# RL6678_IP_SVD register map
Vendor: Realtek
Registers are 32-bit, read-write, reset 0x0 unless marked. A register's access mark holds for its fields unless they carry their own. Offsets are from the block's base; [hi:lo] are bit positions; lines under a group give offsets from that group; {n}, {i} and the like mark numbered series.

## PAGE6 (part 2 of 3)
Base 0x40000000
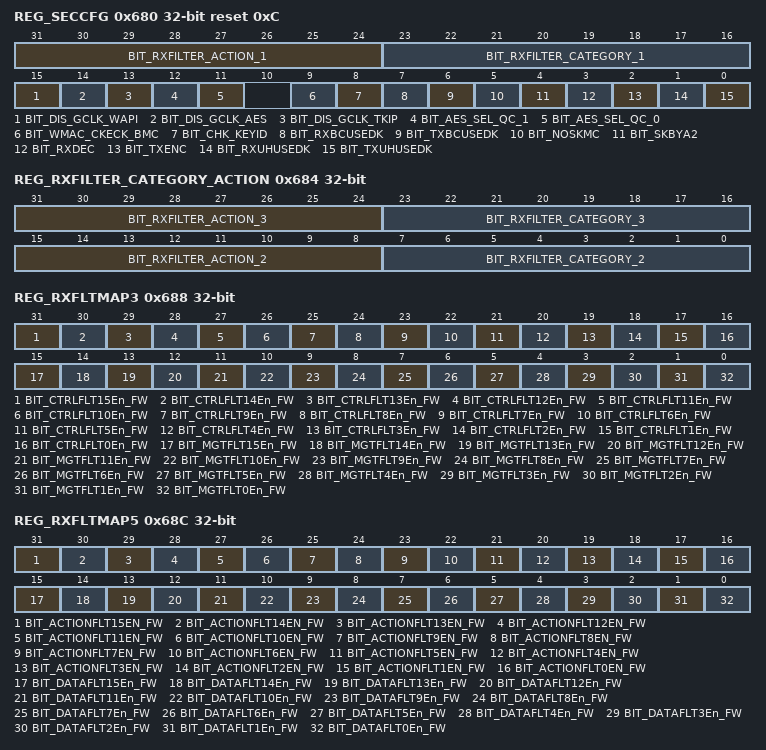
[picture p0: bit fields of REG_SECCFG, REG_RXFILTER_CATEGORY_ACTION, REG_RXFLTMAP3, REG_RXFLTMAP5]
0x680 REG_SECCFG reset 0xC — Security Configuration Register
  [31:24] BIT_RXFILTER_ACTION_1 — Configured by FW, Refer to 0x68E[10] to decide accepting this frame or not
  [23:16] BIT_RXFILTER_CATEGORY_1 — Configured by FW, Refer to 0x68E[10] to decide accepting this frame or not
  [15] BIT_DIS_GCLK_WAPI — Disable gated clock control for WAPI engine
  [14] BIT_DIS_GCLK_AES — Disable gated clock control for AES engine.
  [13] BIT_DIS_GCLK_TKIP — Disable gated clock control for WEP/TKIP engine.
  [12] BIT_AES_SEL_QC_1 — 1: use QC[7] to compute mic 0: not use QC[7] to compute mic
  [11] BIT_AES_SEL_QC_0 — 1:use QC[7] to compute ctr 0: not use QC[7] to compute ctr
  [9] BIT_WMAC_CKECK_BMC — If this bit is set to 1, key search engine need to check if broadcast/multicast bit matched.
  [8] BIT_CHK_KEYID — If this bit is set to 1, key search engine need to check if key ID matched. If this bit is set to 0, then key ID table must be filled with 2"b00.
  [7] BIT_RXBCUSEDK — Force RX Broadcast packets Use Default Key If this bit is set to 1, use default key for RX key search when received packet is broadcast and multicast.
  [6] BIT_TXBCUSEDK — Force Tx Broadcast packets Use Default Key If this bit is set to 1, use default key for TX key search when transmitted packet is broadcast and multicast.
  [5] BIT_NOSKMC — No Key Search for Multicast Setting 1 to disable key search for multicast frames. Used in MBSSID AP mode. Software should manage security encryption and decryption.
  [4] BIT_SKBYA2 — Search Key by A2 Setting 1 to search security CAM by address 2 for TX and search CAM by address 1 for RX. Setting 0 to search security CAM by address 1 for TX and search CAM by address 2 for RX. Used in MBSSID client mode.
  [3] BIT_RXDEC — Enable Rx Decryption Setting 1 to enable Rx hardware decryption.
  [2] BIT_TXENC — Enable Tx Encryption Setting to 1 to enable Tx hardware encryption.
  [1] BIT_RXUHUSEDK — Force RX Unicast Use Default Key If this bit is set to 1, use default key for RX key search when pairwise key is not found.
  [0] BIT_TXUHUSEDK — Force Tx Unicast Use Default Key If this bit is set to 1, use default key for TX key search when pairwise key is not found.
0x684 REG_RXFILTER_CATEGORY_ACTION
  [31:24] BIT_RXFILTER_ACTION_3 — Configured by FW, Refer to 0x68E[15] to decide accepting this frame or not
  [23:16] BIT_RXFILTER_CATEGORY_3 — Configured by FW, Refer to 0x68E[15] to decide accepting this frame or not
  [15:8] BIT_RXFILTER_ACTION_2 — Configured by FW, Refer to 0x68E[11] to decide accepting this frame or not
  [7:0] BIT_RXFILTER_CATEGORY_2 — Configured by FW, Refer to 0x68E[11] to decide accepting this frame or not
0x688 REG_RXFLTMAP3 — RX Filter Map Group 0
  [31] BIT_CTRLFLT15En_FW — When set, frames with type=01 and subtype=1111 are received into FWFF.
  [30] BIT_CTRLFLT14En_FW — When set, frames with type=01 and subtype=1110 are received into FWFF.
  [29] BIT_CTRLFLT13En_FW — When set, frames with type=01 and subtype=1101 are received into FWFF.
  [28] BIT_CTRLFLT12En_FW — When set, frames with type=01 and subtype=1100 are received into FWFF.
  [27] BIT_CTRLFLT11En_FW — When set, frames with type=01 and subtype=1011 are received into FWFF.
  [26] BIT_CTRLFLT10En_FW — When set, frames with type=01 and subtype=1010 are received into FWFF.
  [25] BIT_CTRLFLT9En_FW — When set, frames with type=01 and subtype=1001 are received into FWFF.
  [24] BIT_CTRLFLT8En_FW — When set, frames with type=01 and subtype=1000 are received into FWFF.
  [23] BIT_CTRLFLT7En_FW — When set, frames with type=01 and subtype=0111 are received into FWFF.
  [22] BIT_CTRLFLT6En_FW — When set, frames with type=01 and subtype=0110 are received into FWFF.
  [21] BIT_CTRLFLT5En_FW — When set, frames with type=01 and subtype=0101 are received into FWFF.
  [20] BIT_CTRLFLT4En_FW — When set, frames with type=01 and subtype=0100 are received into FWFF.
  [19] BIT_CTRLFLT3En_FW — When set, frames with type=01 and subtype=0011 are received into FWFF.
  [18] BIT_CTRLFLT2En_FW — When set, frames with type=01 and subtype=0010 are received into FWFF.
  [17] BIT_CTRLFLT1En_FW — When set, frames with type=01 and subtype=0001 are received into FWFF.
  [16] BIT_CTRLFLT0En_FW — When set, frames with type=01 and subtype=0000 are received into FWFF.
  [15] BIT_MGTFLT15En_FW — When set, frames with type=00 and subtype=1111 are received into FWFF.
  [14] BIT_MGTFLT14En_FW — When set, all the frames with type=00 and subtype=1110 are received into FWFF. When set to 0, refer to 0x68E[15:12] for deciding which action noack frames will be accepted
  [13] BIT_MGTFLT13En_FW — When set, all the frames with type=00 and subtype=1101 are received into FWFF. When set to 0, refer to 0x68E[11:0] for deciding which action frames will be accepted
  [12] BIT_MGTFLT12En_FW — When set, frames with type=00 and subtype=1100 are received into FWFF.
  [11] BIT_MGTFLT11En_FW — When set, frames with type=00 and subtype=1011 are received into FWFF.
  [10] BIT_MGTFLT10En_FW — When set, frames with type=00 and subtype=1010 are received into FWFF.
  [9] BIT_MGTFLT9En_FW — When set, frames with type=00 and subtype=1001 are received into FWFF.
  [8] BIT_MGTFLT8En_FW — When set, frames with type=00 and subtype=1000 are received into FWFF.
  [7] BIT_MGTFLT7En_FW — When set, frames with type=00 and subtype=0111 are received into FWFF.
  [6] BIT_MGTFLT6En_FW — When set, frames with type=00 and subtype=0110 are received into FWFF.
  [5] BIT_MGTFLT5En_FW — When set, frames with type=00 and subtype=0101 are received into FWFF.
  [4] BIT_MGTFLT4En_FW — When set, frames with type=00 and subtype=0100 are received into FWFF.
  [3] BIT_MGTFLT3En_FW — When set, frames with type=00 and subtype=0011 are received into FWFF.
  [2] BIT_MGTFLT2En_FW — When set, frames with type=00 and subtype=0010 are received into FWFF.
  [1] BIT_MGTFLT1En_FW — When set, frames with type=00 and subtype=0001 are received into FWFF.
  [0] BIT_MGTFLT0En_FW — When set, frames with type=00 and subtype=0000 are received into FWFF.
0x68C REG_RXFLTMAP5 — RX Filter Map Group 1
  [31] BIT_ACTIONFLT15EN_FW — When set, Action noack frame with category = r_RXFILTER_CATEGORY_3(0x686[7:0]) and action = r_RXFILTER_ACTION_3(0x687[7:0]) will be received into FWFF
  [30] BIT_ACTIONFLT14EN_FW — When set, VHT compressed beamforming frame will be received into FWFF.
  [29] BIT_ACTIONFLT13EN_FW — When set, HT compressed beamforming frame will be received into FWFF.
  [28] BIT_ACTIONFLT12EN_FW — When set, CSI frame will be received into FWFF.
  [27] BIT_ACTIONFLT11EN_FW — When set, Action frame with category = r_RXFILTER_CATEGORY_2(0x684[7:0]) and action = r_RXFILTER_ACTION_2(0x685[7:0]) will be received into FWFF
  [26] BIT_ACTIONFLT10EN_FW — When set, Action frame with category = r_RXFILTER_CATEGORY_1(0x682[7:0]) and action = r_RXFILTER_ACTION_1(0x683[7:0]) will be received into FWFF
  [25] BIT_ACTIONFLT9EN_FW — When set, Operating mode notification frame will be received into FWFF.
  [24] BIT_ACTIONFLT8EN_FW — When set, Group ID Management frame will be received into FWFF.
  [23] BIT_ACTIONFLT7EN_FW — When set, Notify channel width frame will be received into FWFF.
  [22] BIT_ACTIONFLT6EN_FW — When set, DELBA frame will be received into FWFF.
  [21] BIT_ACTIONFLT5EN_FW — When set, ADDBA Response frame will be received into FWFF.
  [20] BIT_ACTIONFLT4EN_FW — When set, ADDBA Request frame will be received into FWFF.
  [19] BIT_ACTIONFLT3EN_FW — When set, DELTS frame will be received into FWFF.
  [18] BIT_ACTIONFLT2EN_FW — When set, ADDTS Response frame will be received into FWFF.
  [17] BIT_ACTIONFLT1EN_FW — When set, ADDTS Request frame will be received into FWFF.
  [16] BIT_ACTIONFLT0EN_FW — When set, Channel Switch Announcement frame will be received into FWFF.
  [15] BIT_DATAFLT15En_FW — When set, frames with type=10 and subtype=1111 are received into FWFF.
  [14] BIT_DATAFLT14En_FW — When set, frames with type=10 and subtype=1110 are received into FWFF.
  [13] BIT_DATAFLT13En_FW — When set, frames with type=10 and subtype=1101 are received into FWFF.
  [12] BIT_DATAFLT12En_FW — When set, frames with type=10 and subtype=1100 are received into FWFF.
  [11] BIT_DATAFLT11En_FW — When set, frames with type=10 and subtype=1011 are received into FWFF.
  [10] BIT_DATAFLT10En_FW — When set, frames with type=10 and subtype=1010 are received into FWFF.
  [9] BIT_DATAFLT9En_FW — When set, frames with type=10 and subtype=1001 are received into FWFF.
  [8] BIT_DATAFLT8En_FW — When set, frames with type=10 and subtype=1000 are received into FWFF.
  [7] BIT_DATAFLT7En_FW — When set, frames with type=10 and subtype=0111 are received into FWFF.
  [6] BIT_DATAFLT6En_FW — When set, frames with type=10 and subtype=0110 are received into FWFF.
  [5] BIT_DATAFLT5En_FW — When set, frames with type=10 and subtype=0101 are received into FWFF.
  [4] BIT_DATAFLT4En_FW — When set, frames with type=10 and subtype=0100 are received into FWFF.
  [3] BIT_DATAFLT3En_FW — When set, frames with type=10 and subtype=0011 are received into FWFF.
  [2] BIT_DATAFLT2En_FW — When set, frames with type=10 and subtype=0010 are received into FWFF.
  [1] BIT_DATAFLT1En_FW — When set, frames with type=10 and subtype=0001 are received into FWFF.
  [0] BIT_DATAFLT0En_FW — When set, frames with type=10 and subtype=0000 are received into FWFF.
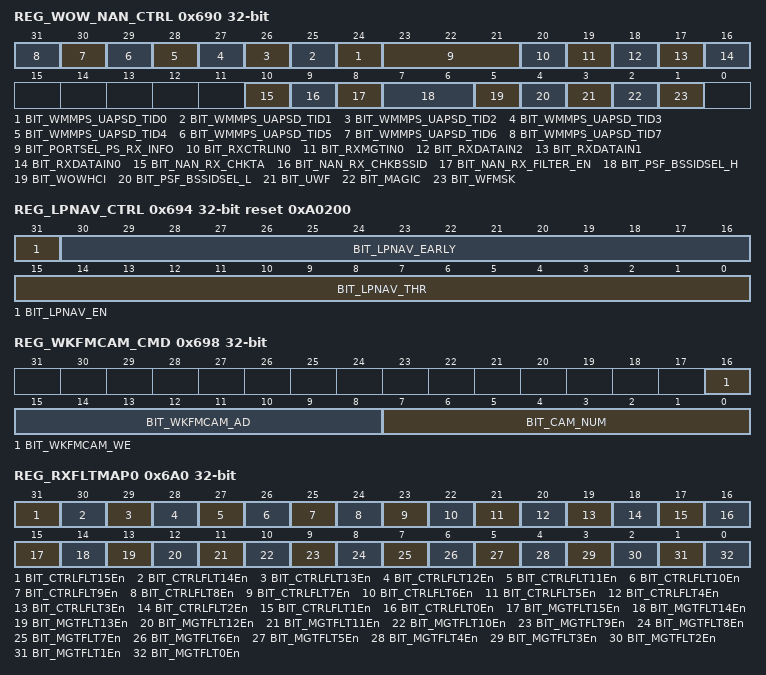
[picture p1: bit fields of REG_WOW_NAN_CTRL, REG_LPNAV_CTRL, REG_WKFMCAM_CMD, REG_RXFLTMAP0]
0x690 REG_WOW_NAN_CTRL access per field — Wake On WLAN and NAN Control Register
  [n+24] BIT_WMMPS_UAPSD_TID{n} rw (n=0..7) — Disable interrupt 8051 when rx WMMPS UAPSD Qos data with TID{n}
  [23:21] BIT_PORTSEL_PS_RX_INFO rw — The selector for the source of PS RX information (0x692[4:0]). 0 for port 0, 1 for clint0, 2 for clint1, 3 for clint2, 4 for clint3.
  [20] BIT_RXCTRLIN0 ro — It is set to 1 if NIC received control frame with correct DA.
  [19] BIT_RXMGTIN0 ro — It is set to 1 if NIC received management frame with correct BSSID and DA (including unicast and BMC).
  [18] BIT_RXDATAIN2 ro — It is set to 1 if NIC received data frame with correct BSSID and DA (including unicast and BMC).
  [17] BIT_RXDATAIN1 ro — It is set to 1 if NIC received data frame with correct BSSID and DA (including unicast and BMC).
  [16] BIT_RXDATAIN0 ro — It is set to 1 if NIC received data frame with correct BSSID and DA (including unicast and BMC).
  [10] BIT_NAN_RX_CHKTA rw — Enable bit for check TSF filter When set to 1, the TSF address filter will enable. When set to 0, the TSF address filter will disable.
  [9] BIT_NAN_RX_CHKBSSID rw — Check BSSID_BCN for TSF When set to 1, MAC will check the BSSID (A3) of RX beacon or Probe to determine if this packet will sync TSF or not
  [8] BIT_NAN_RX_FILTER_EN rw — When set to 1, the TSF address filter will enable. When set to 0, the TSF address filter will disable.
  [7:6] BIT_PSF_BSSIDSEL_H rw — Bit 1,2 of Select to check the MACID of which port for the WMAC PSF NSARP function. 0: to check the MACID of port0; 1: to check the MACID of port1. 2: to check the MACID of port2. 3: to check the MACID of port3. 4: to check the MACID of port4.
  [5] BIT_WOWHCI rw — This bit is set to allow wake host as wake on wlan event occurring
  [4] BIT_PSF_BSSIDSEL_L rw — Bit 0 of Select to check the MACID of which port for the WMAC PSF NSARP function. 0: to check the MACID of port0; 1: to check the MACID of port1. 2: to check the MACID of port2. 3: to check the MACID of port3. 4: to check the MACID of port4.
  [3] BIT_UWF rw — Unicast Packet. 1: Enable to check packet"s DA match MAC address or not. 0: Disable. (default value)
  [2] BIT_MAGIC rw — Magic Packet. This bit is valid when the PMEn bit of the PMR register is set. The RTL8192 will assert the PMEB signal to wakeup the operating system when a Magic Packet is received. Once the RTL8192 has been enabled for Magic Packet wakeup, it scans incoming packets addressed to the node for a data sequence. The correct sequence indicates to the controller that this is a Magic Packet frame. A Magic Packet frame must also meet the basic requirements: Frame Control + Duration/ID + Destination address + Address 2 + Address 3 + Sequence Control + data + CRC. The destination address may be the node ID of the receiving station or a multicast address, including the broadcast address. The specific sequence consists of 16 duplications of 6 byte ID registers, with no breaks or interrupts. This sequence can be located anywhere within the packet, but must be preceded by a synchronization stream, 6 bytes of FFh. The device will also accept a multicast address, as long as the 16 duplications of the IEEE address match the address of the ID registers. If the Node ID is 11h 22h 33h 44h 55h 66h, then the magic frame"s format is as follows: Frame Control + Duration/ID + Destination address + Address 2 + Address 3 + Sequence Control + MISC + FF FF FF FF FF FF + MISC + 11 22 33 44 55 66 + 11 22 33 44 55 66 + 11 22 33 44 55 66 + 11 22 33 44 55 66 + 11 22 33 44 55 66 + 11 22 33 44 55 66 + 11 22 33 44 55 66 + 11 22 33 44 55 66 + 11 22 33 44 55 66 + 11 22 33 44 55 66 + 11 22 33 44 55 66 + 11 22 33 44 55 66 + 11 22 33 44 55 66 + 11 22 33 44 55 66 + 11 22 33 44 55 66 + 11 22 33 44 55 66 + MISC + CRC.
  [1] BIT_WFMSK rw — WoW function on or off.
0x694 REG_LPNAV_CTRL reset 0xA0200 — Low Power NAV Control Register
  [31] BIT_LPNAV_EN — Low Power NAV Mode Enable. When this bit is set, enable MAC low power NAV mode
  [30:16] BIT_LPNAV_EARLY — When in LPNAV mode, MAC will recall BB and RF into RX idle mode. The unit is us.
  [15:0] BIT_LPNAV_THR — When protected NAV in the received frame is greater than this threshold value, then MAC enters into LPNAV mode. The time unit is 16us.
0x698 REG_WKFMCAM_CMD — Wakeup Frame CAM Number Register
  [16] BIT_WKFMCAM_WE — CAM Write Enable
  [15:8] BIT_WKFMCAM_AD — Entry address
  [7:0] BIT_CAM_NUM — CAM Entry Number
0x69C REG_WKFMCAM_WD — Wakeup Frame CAM CONTENT Register
  [31:0] BIT_WKFMCAM_WD — CAM Write Data
0x6A0 REG_RXFLTMAP0 — RX Filter Map Group 0
  [31] BIT_CTRLFLT15En — When set, frames with type=01 and subtype=1111 are received into RXFF
  [30] BIT_CTRLFLT14En — When set, frames with type=01 and subtype=1110 are received into RXFF
  [29] BIT_CTRLFLT13En — When set, frames with type=01 and subtype=1101 are received into RXFF.
  [28] BIT_CTRLFLT12En — When set, frames with type=01 and subtype=1100 are received into RXFF.
  [27] BIT_CTRLFLT11En — When set, frames with type=01 and subtype=1011 are received into RXFF
  [26] BIT_CTRLFLT10En — When set, frames with type=01 and subtype=1010 are received into RXFF.
  [25] BIT_CTRLFLT9En — When set, frames with type=01 and subtype=1001 are received into RXFF
  [24] BIT_CTRLFLT8En — When set, frames with type=01 and subtype=1000 are received into RXFF
  [23] BIT_CTRLFLT7En — When set, frames with type=01 and subtype=0111 are received into RXFF
  [22] BIT_CTRLFLT6En — When set, frames with type=01 and subtype=0110 are received into RXFF.
  [21] BIT_CTRLFLT5En — When set, frames with type=01 and subtype=0101 are received into RXFF.
  [20] BIT_CTRLFLT4En — When set, frames with type=01 and subtype=0100 are received into RXFF.
  [19] BIT_CTRLFLT3En — When set, frames with type=01 and subtype=0011 are received into RXFF.
  [18] BIT_CTRLFLT2En — When set, frames with type=01 and subtype=0010 are received into RXFF.
  [17] BIT_CTRLFLT1En — When set, frames with type=01 and subtype=0001 are received into RXFF.
  [16] BIT_CTRLFLT0En — When set, frames with type=01 and subtype=0000 are received into RXFF.
  [15] BIT_MGTFLT15En — When set, frames with type=00 and subtype=1111 are received into RXFF.
  [14] BIT_MGTFLT14En — When set, frames with type=00 and subtype=1110 are received into RXFF.
  [13] BIT_MGTFLT13En — When set, frames with type=00 and subtype=1101 are received into RXFF.
  [12] BIT_MGTFLT12En — When set, frames with type=00 and subtype=1100 are received into RXFF.
  [11] BIT_MGTFLT11En — When set, frames with type=00 and subtype=1011 are received into RXFF.
  [10] BIT_MGTFLT10En — When set, frames with type=00 and subtype=1010 are received into RXFF
  [9] BIT_MGTFLT9En — When set, frames with type=00 and subtype=1001 are received into RXFF.
  [8] BIT_MGTFLT8En — When set, frames with type=00 and subtype=1000 are received into RXFF
  [7] BIT_MGTFLT7En — When set, frames with type=00 and subtype=0111 are received into RXFF.
  [6] BIT_MGTFLT6En — When set, frames with type=00 and subtype=0110 are received into RXFF.
  [5] BIT_MGTFLT5En — When set, frames with type=00 and subtype=0101 are received into RXFF
  [4] BIT_MGTFLT4En — When set, frames with type=00 and subtype=0100 are received into RXFF.
  [3] BIT_MGTFLT3En — When set, frames with type=00 and subtype=0011 are received into RXFF
  [2] BIT_MGTFLT2En — When set, frames with type=00 and subtype=0010 are received into RXFF
  [1] BIT_MGTFLT1En — When set, frames with type=00 and subtype=0001 are received into RXFF
  [0] BIT_MGTFLT0En — When set, frames with type=00 and subtype=0000 are received into RXFF
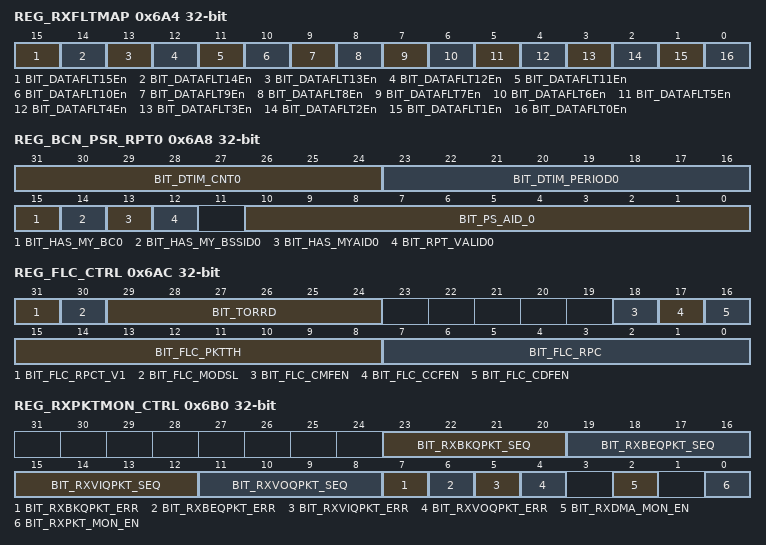
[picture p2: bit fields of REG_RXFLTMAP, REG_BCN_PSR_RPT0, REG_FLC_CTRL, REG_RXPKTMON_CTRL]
0x6A4 REG_RXFLTMAP — RX Filter Map Group 1
  [15] BIT_DATAFLT15En — When set, frames with type=10 and subtype=1111 are received into RXFF
  [14] BIT_DATAFLT14En — When set, frames with type=10 and subtype=1110 are received into RXFF
  [13] BIT_DATAFLT13En — When set, frames with type=10 and subtype=1101 are received into RXFF.
  [12] BIT_DATAFLT12En — When set, frames with type=10 and subtype=1100 are received into RXFF.
  [11] BIT_DATAFLT11En — When set, frames with type=10 and subtype=1011 are received into RXFF.
  [10] BIT_DATAFLT10En — When set, frames with type=10 and subtype=1010 are received into RXFF.
  [9] BIT_DATAFLT9En — When set, frames with type=10 and subtype=1001 are received into RXFF
  [8] BIT_DATAFLT8En — When set, frames with type=10 and subtype=1000 are received into RXFF
  [7] BIT_DATAFLT7En — When set, frames with type=10 and subtype=0111 are received into RXFF.
  [6] BIT_DATAFLT6En — When set, frames with type=10 and subtype=0110 are received into RXFF
  [5] BIT_DATAFLT5En — When set, frames with type=10 and subtype=0101 are received into RXFF
  [4] BIT_DATAFLT4En — When set, frames with type=10 and subtype=0100 are received into RXFF.
  [3] BIT_DATAFLT3En — When set, frames with type=10 and subtype=0011 are received into RXFF
  [2] BIT_DATAFLT2En — When set, frames with type=10 and subtype=0010 are received into RXFF.
  [1] BIT_DATAFLT1En — When set, frames with type=10 and subtype=0001 are received into RXFF.
  [0] BIT_DATAFLT0En — When set, frames with type=10 and subtype=0000 are received into RXFF.
0x6A8 REG_BCN_PSR_RPT0 access per field — Beacon Parser Report Register
  [31:24] BIT_DTIM_CNT0 ro — The DTIM count field of the TIM element of Rx beacon
  [23:16] BIT_DTIM_PERIOD0 ro — The DTIM period field of the TIM element of Rx beacon
  [15] BIT_HAS_MY_BC0 ro — Indicate BC/MC packets are buffered in transmitted BSSID or AP
  [14] BIT_HAS_MY_BSSID0 ro — Indicate BC/MC packets are buffered in nontransmitted BSSID, SW need check crespponding dtim count field in multiple bssid index field
  [13] BIT_HAS_MYAID0 ro — Indicate has my unicast packet
  [12] BIT_RPT_VALID0 ro — when set to 1, indicate the tim report is valid
  [10:0] BIT_PS_AID_0 rw — AID0 for MACID
0x6AC REG_FLC_CTRL access per field — FW LPS Condition PKT Counter
  [31] BIT_FLC_RPCT_V1 rw — When write "1" to this bit, FLC_TRPC will be enabled.
  [30] BIT_FLC_MODSL rw — 1:Timer Mode 0:Counter Mode
  [29:24] BIT_TORRD rw — It specifies the time-out duration. (unit: 32 ms)
  [18] BIT_FLC_CMFEN rw — Count Management Frame (1: Enable, 0:Disable)
  [17] BIT_FLC_CCFEN rw — Count Control Frame (1: Enable, 0:Disable)
  [16] BIT_FLC_CDFEN rw — Count Data Frame (1: Enable, 0:Disable)
  [15:8] BIT_FLC_PKTTH rw — Rx PKT number threshold
  [7:0] BIT_FLC_RPC ro — Number of Rx PKT in the interval which is specified by FLC_TRPC. The Rx PKT type is specified by 0x6AE[2:0]
0x6B0 REG_RXPKTMON_CTRL access per field
  [23:20] BIT_RXBKQPKT_SEQ ro — The expected Rx BKQ packet index
  [19:16] BIT_RXBEQPKT_SEQ ro — The expected Rx BEQ packet index
  [15:12] BIT_RXVIQPKT_SEQ ro — The expected Rx VIQ packet index
  [11:8] BIT_RXVOQPKT_SEQ ro — The expected Rx VOQ packet index
  [7] BIT_RXBKQPKT_ERR ro — Indicate monitor find the Rx BKQ packet without incremental index
  [6] BIT_RXBEQPKT_ERR ro — Indicate monitor find the Rx BEQ packet without incremental index
  [5] BIT_RXVIQPKT_ERR ro — Indicate monitor find the Rx VIQ packet without incremental index
  [4] BIT_RXVOQPKT_ERR ro — Indicate monitor find the Rx VOQ packet without incremental index
  [2] BIT_RXDMA_MON_EN rw — Enable packet loss monitor function for Rx DMA. If this bit is set to 1, then MACRX append the incremental index to fragment field of sequence number field of rxmpdu restored to rxpkbuffer successfully
  [0] BIT_RXPKT_MON_EN rw — Enable packet loss monitor function for Rx packets. If this bit is set to 1, then MACRX uses fragment field of sequence number field of rxmpdu as the mpdu index and check if the index is incremental.
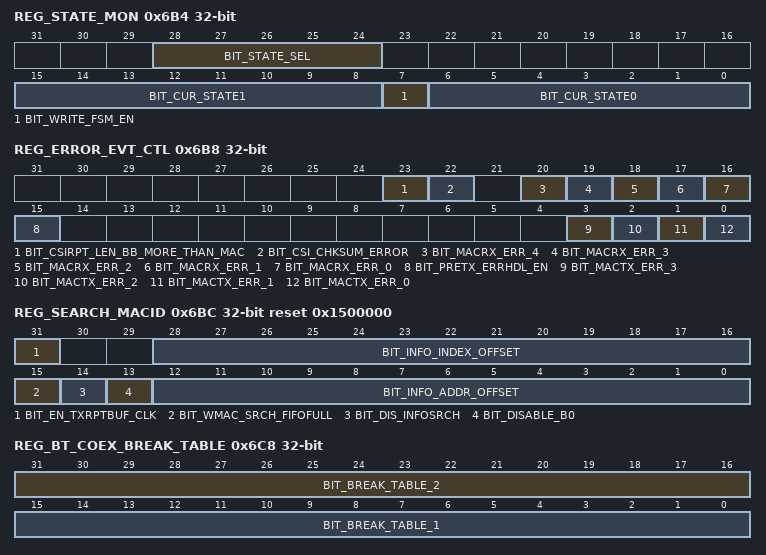
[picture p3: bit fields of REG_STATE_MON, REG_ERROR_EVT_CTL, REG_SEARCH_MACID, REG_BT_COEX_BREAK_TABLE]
0x6B4 REG_STATE_MON access per field
  [28:24] BIT_STATE_SEL rw — WMAC read and write FSM selection: 000,001:read mactx status 010,011:read mactx status 100:read response status 00xxx: write [6:0]to mactx fsm when [7] valid 01xxx:write [6:0]to macrx fsm when [7] valid 100xx: write [6:0]to response fsm when [7] valid
  [15:8] BIT_CUR_STATE1 ro — when BIT_WRITE_FSM_EN is valid,is rsvd. When BIT_WRITE_FSM_EN is not valid, means read status
  [7] BIT_WRITE_FSM_EN ro — when set 1, generate write pulse, otherwise means read status
  [6:0] BIT_CUR_STATE0 rw — when BIT_WRITE_FSM_EN is valid,Indicate the FSM current state to write. When BIT_WRITE_FSM_EN is not valid, means read status
0x6B8 REG_ERROR_EVT_CTL access per field
  [23] BIT_CSIRPT_LEN_BB_MORE_THAN_MAC ro — Indicate MAC Rx csi rxd number overflow
  [22] BIT_CSI_CHKSUM_ERROR ro — Indicate MAC Rx csi rpt checksum error
  [20] BIT_MACRX_ERR_4 ro — Indicate last MPDU length of AMPDU or PPDU length is error.
  [19] BIT_MACRX_ERR_3 ro — Indicate rxfifo or mac phy interface fifo overflow
  [18] BIT_MACRX_ERR_2 ro — Indicate MAC Rx occurs internal halt event
  [17] BIT_MACRX_ERR_1 ro — Indicate Rx packet length >= 12K bytes
  [16] BIT_MACRX_ERR_0 ro — Indicate MAC Rx occurs halt event
  [15] BIT_PRETX_ERRHDL_EN rw — Pre tx error block enable signal
  [3] BIT_MACTX_ERR_3 ro — Indicate PHY fetch plcp before it is ready
  [2] BIT_MACTX_ERR_2 ro — phy_txen is set ,but wait phy_phytxon time out
  [1] BIT_MACTX_ERR_1 ro — Indicate TXD FIFO underflow,ppdu fetch zld
  [0] BIT_MACTX_ERR_0 ro — Indicate TXD FIFO underflow,mpdu fetch zld
0x6BC REG_SEARCH_MACID reset 0x1500000
  [31] BIT_EN_TXRPTBUF_CLK — when set to 1,keep txrptbuf sram always have clock
  [28:16] BIT_INFO_INDEX_OFFSET — Pre-macid information index address offset.
  [15] BIT_WMAC_SRCH_FIFOFULL — when set to 1, when fifofull, stop macid search;
  [14] BIT_DIS_INFOSRCH — when set to 1,disable to search information
  [13] BIT_DISABLE_B0 — when set to 1,disable to check a2[0]
  [12:0] BIT_INFO_ADDR_OFFSET — per-macid information address offset (Unit:8bytes).
0x6C0 REG_BT_COEX_TABLE_V1 — BT Coexistence Control register
  [31:0] BIT_COEX_TABLE_1 — coexistence table, used at dual antenna & out of band
0x6C4 REG_BT_COEX_TABLE2_V1 — BTCoexistence Control register
  [31:0] BIT_COEX_TABLE_2 — coexistence table, used at dual antenna & in band or single antenna
0x6C8 REG_BT_COEX_BREAK_TABLE — BT Coexistence Control register
  [31:16] BIT_BREAK_TABLE_2 — Table used to break BT activity, when new WLAN request is coming and BT is on transmitting or receiving
  [15:0] BIT_BREAK_TABLE_1 — Table used to break WLAN activity, when new BT request is coming and WLAN is on transmitting or receiving
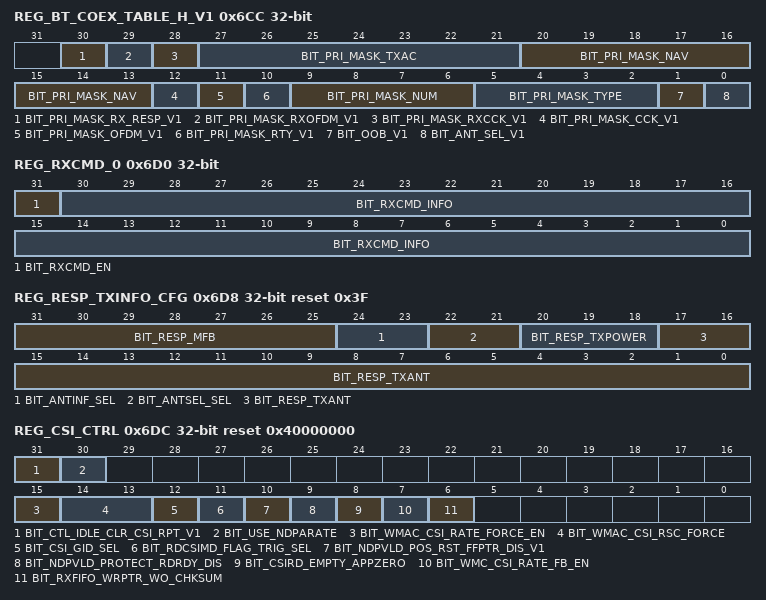
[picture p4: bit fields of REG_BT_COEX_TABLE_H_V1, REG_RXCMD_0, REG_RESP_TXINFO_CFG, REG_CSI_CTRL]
0x6CC REG_BT_COEX_TABLE_H_V1 — BT Coexistence Control register
  [30] BIT_PRI_MASK_RX_RESP_V1 — Priority Mask for RX Response Packet
  [29] BIT_PRI_MASK_RXOFDM_V1 — Priority Mask for RX OFDM
  [28] BIT_PRI_MASK_RXCCK_V1 — Priority Mask for RX CCK
  [27:21] BIT_PRI_MASK_TXAC — Priority Mask for Tx Queue
  [20:13] BIT_PRI_MASK_NAV — Priority Mask for Tx NAV
  [12] BIT_PRI_MASK_CCK_V1 — Priority Mask for Tx CCK
  [11] BIT_PRI_MASK_OFDM_V1 — Priority Mask for Tx OFDM
  [10] BIT_PRI_MASK_RTY_V1 — Priority Mask for Tx Retry Packet
  [9:6] BIT_PRI_MASK_NUM — Priority Mask for Tx packet number
  [5:2] BIT_PRI_MASK_TYPE — Priority Mask for Tx packet type [98]: Rx response [99]: Tx response [100]: beacon
  [1] BIT_OOB_V1 — out of band indication (0: in band ; 1 : out of band)
  [0] BIT_ANT_SEL_V1 — single or dual antenna selection (0: single; 1 : dual)
0x6D0 REG_RXCMD_0
  [31] BIT_RXCMD_EN — RXCMD function enable
  [30:0] BIT_RXCMD_INFO — The Information is send to rxpktbuffer for host SW
0x6D4 REG_RXCMD_1
  [15:0] BIT_RXCMD_PRD — Define the period unit in us to send the RXCMD_INFO to rxpktbuffer for host SW
0x6D8 REG_RESP_TXINFO_CFG reset 0x3F
  [31:25] BIT_RESP_MFB — MFB information in register for response packet
  [24:23] BIT_ANTINF_SEL — Antsel information for response frame in register or ctrl info 00: Antsel_en always disable, 01:Antsel_en field follow ctrl info 1X:Antsel_en always enable
  [22:21] BIT_ANTSEL_SEL — antenna select 0: use rx phystatus antsel information; 1: use tx report antsel information; other: use register antsel information.
  [20:18] BIT_RESP_TXPOWER — tx power setting when send response packet
  [17:0] BIT_RESP_TXANT — tx antenna information
0x6DC REG_CSI_CTRL reset 0x40000000
  [31] BIT_CTL_IDLE_CLR_CSI_RPT_V1 — ckr csi report request if response fsm idle
  [30] BIT_USE_NDPARATE — 1: use ndpa rx rate to decide csi report rate 0: use ndp rx rate to decide csi report rate
  [15] BIT_WMAC_CSI_RATE_FORCE_EN — 0: disable CSI force rate. Refer to RRSR bitmask 1: CSI frame Tx rate refers to 0x6DC[29:24]
  [14:13] BIT_WMAC_CSI_RSC_FORCE — If csi_force_rate_en = 1, CSI frame sub-channel configuration 00: Primary 20Mhz BW(0x483[3:0]) 01: Follow Rx packet BW. 10: Duplicate mode. 11: Reserved
  [12] BIT_CSI_GID_SEL — SIG-A content 1 : group id=0, 0 : group id=63
  [11] BIT_RDCSIMD_FLAG_TRIG_SEL — 0: Trigger read csi mode flag raising when mac_csi_granted & ndp_valid positive edge 1: Trigger read csi mode flag raising when mac_csi_granted positive edge
  [10] BIT_NDPVLD_POS_RST_FFPTR_DIS_V1 — 0: Reset rx_fifo read/wrtie pointer when ndp_valid positive edge 1: Not reset rx_fifo read/wrtie pointer when ndp_valid positive edge
  [9] BIT_NDPVLD_PROTECT_RDRDY_DIS — 0: Protect write enable of rx_fifo when ndp_valid =1 1: Not Protect write enable of rx_fifo when ndp_valid =1
  [8] BIT_CSIRD_EMPTY_APPZERO — 0: Not append zero data when rx_fifo read csi data to empty. If csi data length of BB transmitted is smaller than MAC expected, Tx CSI report would be FCS error. 1: Append zero data when rx_fifo read csi data to empty. If csi data length of BB transmitted is smaller than MAC expected, there would be zero before FCS field of Tx CSI report pkt and the CSI report pkt would be FCS ok
  [7] BIT_WMC_CSI_RATE_FB_EN — Enable CSI frame rate fallback (only one step in CSI RRSR) This bit is set to 1 to enable MAC to use previous latched csi resp rate for retry pkt.
  [6] BIT_RXFIFO_WRPTR_WO_CHKSUM — This bit is set to 1 when rx_fifo don't enable csi data checksum.
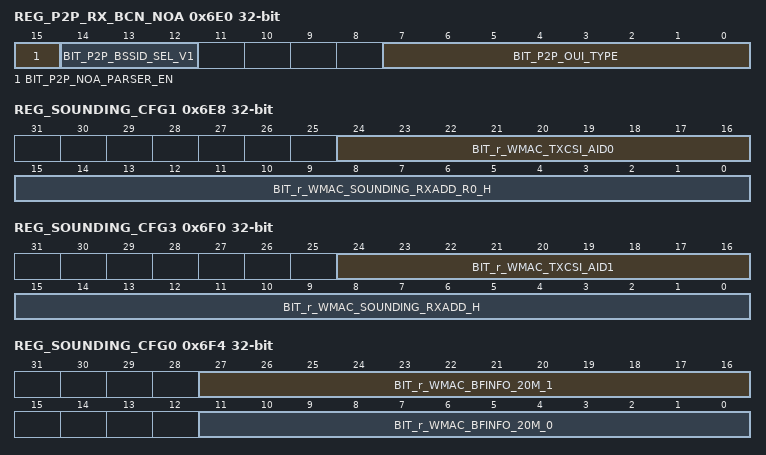
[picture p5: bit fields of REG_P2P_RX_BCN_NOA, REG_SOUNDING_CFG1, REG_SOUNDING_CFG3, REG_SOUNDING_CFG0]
0x6E0 REG_P2P_RX_BCN_NOA
  [15] BIT_P2P_NOA_PARSER_EN — NoA Parser enabled.
  [14:12] BIT_P2P_BSSID_SEL_V1 — When this valueis 0/1/2/3/4, then beacon with matched BSSID0/1/2/3/4 is parsed.
  [7:0] BIT_P2P_OUI_TYPE — NOA OUI Type
0x6E4 REG_ASSOCIATED_BFMER0_INFO — Associated Beamformer0 Info Register
  [31:0] BIT_r_WMAC_SOUNDING_RXADD_R0_V1 — MACID of the associated beamformer0 bit[31:0]
0x6E8 REG_SOUNDING_CFG1
  [24:16] BIT_r_WMAC_TXCSI_AID0 — P_AID of the associated bemaformer0
  [15:0] BIT_r_WMAC_SOUNDING_RXADD_R0_H — MACID of the associated beamformer0 bit[47:32]
0x6EC REG_SOUNDING_CFG2
  [31:0] BIT_r_WMAC_SOUNDING_RXADD_L — MACID of the associated beamformer1 bit[31:0]
0x6F0 REG_SOUNDING_CFG3
  [24:16] BIT_r_WMAC_TXCSI_AID1 — P_AID of the associated bemaformer1
  [15:0] BIT_r_WMAC_SOUNDING_RXADD_H — MACID of the associated beamformer1 bit[15:0]
0x6F4 REG_SOUNDING_CFG0
  [27:16] BIT_r_WMAC_BFINFO_20M_1 — BF Info of the associated beamformer1 at BW=20M bit[18:16]: Nc index bit[21:19]: Nr index bit[23:22]: grouping bit[25:24]: codebook info bit[27:26]: coefficient size
  [11:0] BIT_r_WMAC_BFINFO_20M_0 — BF Info of the associated beamformer0 at BW=20M bit[2:0]: Nc index bit[5:3]: Nr index bit[7:6]: grouping bit[9:8]: codebook info bit[11:10]: coefficient size
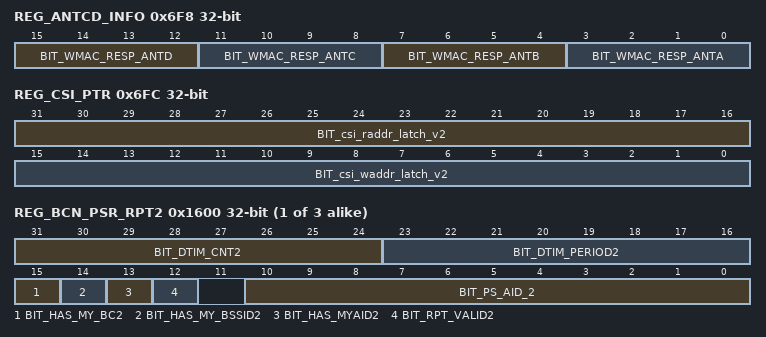
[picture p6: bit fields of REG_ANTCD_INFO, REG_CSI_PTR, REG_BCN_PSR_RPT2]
0x6F8 REG_ANTCD_INFO
  [15:12] BIT_WMAC_RESP_ANTD — used for antenna select d value BIT_WMAC_RESP_ANTCD[3:2], used for antsel_d value;
  [11:8] BIT_WMAC_RESP_ANTC — used for antenna select c value BIT_WMAC_RESP_ANTCD[3:3], used for antsel_d value;
  [7:4] BIT_WMAC_RESP_ANTB — used for antenna select b value BIT_WMAC_RESP_ANTCD[3:4], used for antsel_d value;
  [3:0] BIT_WMAC_RESP_ANTA — used for antenna select a value BIT_WMAC_RESP_ANTCD[3:5], used for antsel_d value;
0x6FC REG_CSI_PTR ro
  [31:16] BIT_csi_raddr_latch_v2 — Tx_fifo read pointer latch value after Tx CSI report pkt (unit: 8B)
  [15:0] BIT_csi_waddr_latch_v2 — Tx_fifo write pointer latch value at ndp_valid negative edge (unit: 8B)
{0x15F8+4i} REG_BCN_PSR_RPT{i} access per field (i=2..4) — Beacon Parser Report Register{i}
  [31:24] BIT_DTIM_CNT{i} ro — The DTIM count field of the TIM element of Rx beacon
  [23:16] BIT_DTIM_PERIOD{i} ro — The DTIM period field of the TIM element of Rx beacon
  [15] BIT_HAS_MY_BC{i} ro — Indicate BC/MC packets are buffered in transmitted BSSID or AP
  [14] BIT_HAS_MY_BSSID{i} ro — Indicate BC/MC packets are buffered in nontransmitted BSSID, SW need check crespponding dtim count field in multiple bssid index field
  [13] BIT_HAS_MYAID{i} ro — Indicate has my unicast packet
  [12] BIT_RPT_VALID{i} ro — when set to 1, indicate the tim report is valid
  [10:0] BIT_PS_AID_{i} rw — AID0 for MACID
